AUTOSAR XML (schema 4-3-0)
package /BcmSystem/SwComponentTypes
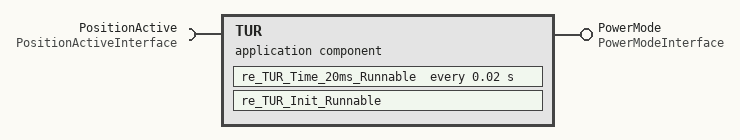
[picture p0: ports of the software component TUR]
  application sw component type TUR
    require port PositionActive: required-interface=PositionActiveInterface
    provide port PowerMode: provided-interface=PowerModeInterface
    behavior TUR_IB: handle-termination-and-restart=NO-SUPPORT
      init event ie_TUR_Init_Runnable: start-on-event=re_TUR_Init_Runnable
      timing event te_TUR_Time_20ms_Runnable: start-on-event=re_TUR_Time_20ms_Runnable, period=0.02
      runnable re_TUR_Init_Runnable: symbol=TUR_Init_Runnable
      runnable re_TUR_Time_20ms_Runnable: symbol=TUR_Time_20ms_Runnable
package /BcmSystem/SwImplementations
  swc implementation SwcImpTUR: programming-language=C, sw-version=1.0.0, vendor-id=0, behavior=TUR_IB
    code-descriptors:
      code CodeTUR: artifact-descriptors=autosar-engineering-object={short-label=SwSrcTUR, category=SWSRC}
